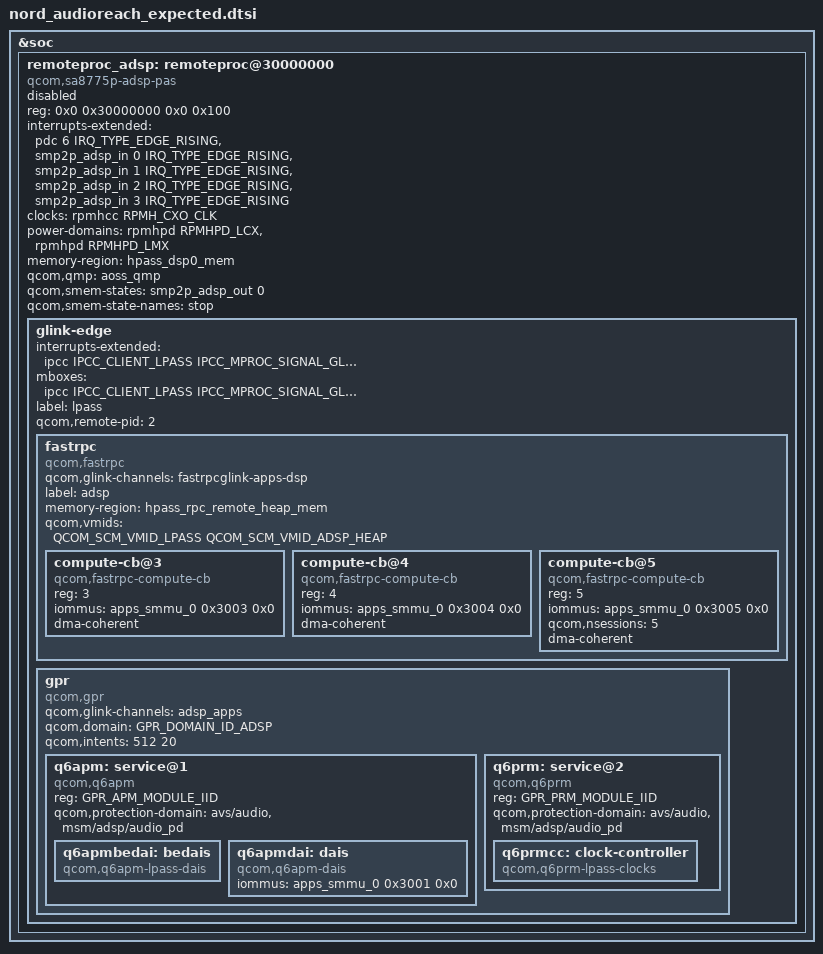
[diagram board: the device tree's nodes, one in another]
/*
 * Generated by Phase-2B WP6 audioreach_topology.
 * Deterministic. No timestamps.
 *
 * Nord IQ-10 AudioReach GPR service tree. Introduces the ADSP
 * remoteproc PAS node (a fresh child of soc — Nord has no
 * pre-existing ADSP remoteproc to overlay) carrying the glink-edge
 * with fastrpc compute-callback edges and the GPR service tree
 * (q6apm with its front-end/back-end DAIs, q6prm with its LPASS
 * clock controller). Ported from linux-nord/0003-*.patch.
 */

&soc {
	/*
	 * ADSP (audio DSP) remoteproc + AudioReach service stack.
	 * Ported from the SA8775P "lemans" reference — the qcom_q6v5_pas
	 * driver already supports the "qcom,sa8775p-adsp-pas" compatible
	 * (firmware adsp.mbn, pas_id 1, proxy PDs lcx/lmx). Placed here
	 * (not nord.dtsi) because it wires to &rpmhcc / &rpmhpd, which are
	 * IQ-10-specific; the SCMI-managed sa8797p-ride path must not pull
	 * these phandles.
	 *
	 * TO BE REVIEWED — first-pass draft for SA8797P. Open items:
	 *   reg base 0x30000000: matches the SA8775P/lemans layout (per IPCAT
	 *     and the upstream QCS9100 DT series). NOTE: downstream Nord boot
	 *     logs show the ADSP PAS at "7000000.remoteproc-adsp" (base
	 *     0x07000000), so the upstream base is NOT yet cross-confirmed for
	 *     SA8797P — reconcile 0x30000000 vs 0x07000000 against the SA8797P
	 *     memory map before trusting on-board. FIXME(sa8797p-audio).
	 *   FIXME(sa8797p-audio): power-domains reference RPMHPD_LCX/LMX, but
	 *     this is WRONG for Nord. "qcom,nord-rpmhpd" does NOT expose
	 *     LCX/LMX; downstream Nord uses SCMI power domains for the ADSP,
	 *     not rpmhpd. The ADSP PAS will NOT probe as drafted; the
	 *     SCMI-vs-rpmhpd power model MUST be resolved before enabling.
	 *   FIXME(sa8797p-audio): the "interconnects" LPASS-NoC path is
	 *     intentionally OMITTED — Nord has no lpass_ag_noc provider.
	 *   FIXME(sa8797p-audio): apps_smmu stream IDs for fastrpc / q6apmdai
	 *     assumed on apps_smmu_0 (0x300x SIDs); confirm which SMMU owns
	 *     the ADSP streams.
	 */
	remoteproc_adsp: remoteproc@30000000 {
		compatible = "qcom,sa8775p-adsp-pas";
		reg = <0x0 0x30000000 0x0 0x100>;

		interrupts-extended = <&pdc 6 IRQ_TYPE_EDGE_RISING>,
				      <&smp2p_adsp_in 0 IRQ_TYPE_EDGE_RISING>,
				      <&smp2p_adsp_in 1 IRQ_TYPE_EDGE_RISING>,
				      <&smp2p_adsp_in 2 IRQ_TYPE_EDGE_RISING>,
				      <&smp2p_adsp_in 3 IRQ_TYPE_EDGE_RISING>;
		interrupt-names = "wdog", "fatal", "ready", "handover",
				  "stop-ack";

		clocks = <&rpmhcc RPMH_CXO_CLK>;
		clock-names = "xo";

		power-domains = <&rpmhpd RPMHPD_LCX>,
				<&rpmhpd RPMHPD_LMX>;
		power-domain-names = "lcx", "lmx";

		memory-region = <&hpass_dsp0_mem>;

		qcom,qmp = <&aoss_qmp>;

		qcom,smem-states = <&smp2p_adsp_out 0>;
		qcom,smem-state-names = "stop";

		status = "disabled";

		glink-edge {
			interrupts-extended = <&ipcc IPCC_CLIENT_LPASS
						     IPCC_MPROC_SIGNAL_GLINK_QMP
						     IRQ_TYPE_EDGE_RISING>;
			mboxes = <&ipcc IPCC_CLIENT_LPASS
					IPCC_MPROC_SIGNAL_GLINK_QMP>;

			label = "lpass";
			qcom,remote-pid = <2>;

			/* FIXME(audioreach_topology_blob): AudioReach APM module
			 * graph (module IIDs, port wiring, connection matrix) is NOT
			 * declared in device tree — it is loaded at runtime by the
			 * q6apm firmware from an ACDB (Audio Calibration Database)
			 * blob. This DT node establishes the GPR service entry points
			 * only. The topology blob itself is a separate deliverable
			 * (firmware bundle).
			 */

			fastrpc {
				compatible = "qcom,fastrpc";
				qcom,glink-channels = "fastrpcglink-apps-dsp";
				label = "adsp";
				memory-region = <&hpass_rpc_remote_heap_mem>;
				qcom,vmids = <QCOM_SCM_VMID_LPASS
						  QCOM_SCM_VMID_ADSP_HEAP>;
				#address-cells = <1>;
				#size-cells = <0>;

				compute-cb@3 {
					compatible = "qcom,fastrpc-compute-cb";
					reg = <3>;
					iommus = <&apps_smmu_0 0x3003 0x0>;
					dma-coherent;
				};

				compute-cb@4 {
					compatible = "qcom,fastrpc-compute-cb";
					reg = <4>;
					iommus = <&apps_smmu_0 0x3004 0x0>;
					dma-coherent;
				};

				compute-cb@5 {
					compatible = "qcom,fastrpc-compute-cb";
					reg = <5>;
					iommus = <&apps_smmu_0 0x3005 0x0>;
					qcom,nsessions = <5>;
					dma-coherent;
				};
			};

			gpr {
				compatible = "qcom,gpr";
				qcom,glink-channels = "adsp_apps";
				qcom,domain = <GPR_DOMAIN_ID_ADSP>;
				qcom,intents = <512 20>;
				#address-cells = <1>;
				#size-cells = <0>;

				q6apm: service@1 {
					compatible = "qcom,q6apm";
					reg = <GPR_APM_MODULE_IID>;
					#sound-dai-cells = <0>;
					qcom,protection-domain = "avs/audio",
								 "msm/adsp/audio_pd";

					q6apmbedai: bedais {
						compatible = "qcom,q6apm-lpass-dais";
						#sound-dai-cells = <1>;
					};

					q6apmdai: dais {
						compatible = "qcom,q6apm-dais";
						iommus = <&apps_smmu_0 0x3001 0x0>;
					};
				};

				q6prm: service@2 {
					compatible = "qcom,q6prm";
					reg = <GPR_PRM_MODULE_IID>;
					qcom,protection-domain = "avs/audio",
								 "msm/adsp/audio_pd";

					q6prmcc: clock-controller {
						compatible = "qcom,q6prm-lpass-clocks";
						#clock-cells = <2>;
					};
				};
			};
		};
	};
};
